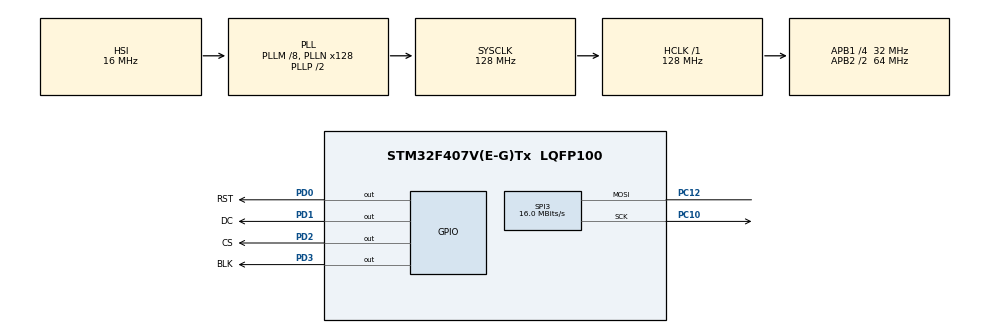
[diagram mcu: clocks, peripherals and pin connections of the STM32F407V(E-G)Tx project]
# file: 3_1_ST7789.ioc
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Mcu.Family=STM32F4
Mcu.Name=STM32F407V(E-G)Tx
Mcu.Package=LQFP100
NVIC.PriorityGroup=NVIC_PRIORITYGROUP_4
PC10.Mode=Simplex_Bidirectional_Master
PC10.Signal=SPI3_SCK
PC12.Mode=Simplex_Bidirectional_Master
PC12.Signal=SPI3_MOSI
PD0.GPIO_Label=RST
PD0.GPIO_PuPd=GPIO_PULLUP
PD0.Signal=GPIO_Output
PD1.GPIO_Label=DC
PD1.Signal=GPIO_Output
PD2.GPIO_Label=CS
PD2.GPIO_PuPd=GPIO_PULLUP
PD2.Signal=GPIO_Output
PD3.GPIO_Label=BLK
PD3.GPIO_PuPd=GPIO_PULLDOWN
PD3.Signal=GPIO_Output
ProjectManager.HeapSize=0x200
ProjectManager.StackSize=0x400
ProjectManager.TargetToolchain=STM32CubeIDE
RCC.48MHZClocksFreq_Value=64000000
RCC.AHBFreq_Value=128000000
RCC.APB1CLKDivider=RCC_HCLK_DIV4
RCC.APB1Freq_Value=32000000
RCC.APB1TimFreq_Value=64000000
RCC.APB2CLKDivider=RCC_HCLK_DIV2
RCC.APB2Freq_Value=64000000
RCC.APB2TimFreq_Value=128000000
RCC.CortexFreq_Value=128000000
RCC.HCLKFreq_Value=128000000
RCC.HSE_VALUE=25000000
RCC.HSI_VALUE=16000000
RCC.LSE_VALUE=32768
RCC.PLLM=8
RCC.PLLN=128
RCC.SYSCLKFreq_VALUE=128000000
RCC.SYSCLKSource=RCC_SYSCLKSOURCE_PLLCLK
RCC.VCOOutputFreq_Value=256000000
SPI3.CLKPolarity=SPI_POLARITY_LOW
SPI3.CalculateBaudRate=16.0 MBits/s
SPI3.Direction=SPI_DIRECTION_1LINE
SPI3.Mode=SPI_MODE_MASTER
SPI3.VirtualType=VM_MASTER
board=custom

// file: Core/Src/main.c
/* USER CODE BEGIN Header */
/**
  ******************************************************************************
  * @file           : main.c
  * @brief          : Main program body
  ******************************************************************************
  * @attention
  *
  * Copyright (c) 2024 STMicroelectronics.
  * All rights reserved.
  *
  * This software is licensed under terms that can be found in the LICENSE file
  * in the root directory of this software component.
  * If no LICENSE file comes with this software, it is provided AS-IS.
  *
  ******************************************************************************
  */
/* USER CODE END Header */
#include <ST7789.h>
#include "main.h"
#include "spi.h"
#include "gpio.h"

void SystemClock_Config(void);

int main(void)
{

  /* MCU Configuration--------------------------------------------------------*/

  /* Reset of all peripherals, Initializes the Flash interface and the Systick. */
  HAL_Init();

  /* Configure the system clock */
  SystemClock_Config();

  /* Initialize all configured peripherals */
  MX_GPIO_Init();
  MX_SPI3_Init();
  /* USER CODE BEGIN 2 */
  ST7789_Init();
  ST7789_DrawAradLogo();
  /* USER CODE END 2 */

  /* Infinite loop */
  while (1)
  {

  }
}

void SystemClock_Config(void)
{
  RCC_OscInitTypeDef RCC_OscInitStruct = {0};
  RCC_ClkInitTypeDef RCC_ClkInitStruct = {0};

  /** Configure the main internal regulator output voltage
  */
  __HAL_RCC_PWR_CLK_ENABLE();
  __HAL_PWR_VOLTAGESCALING_CONFIG(PWR_REGULATOR_VOLTAGE_SCALE1);

  /** Initializes the RCC Oscillators according to the specified parameters
  * in the RCC_OscInitTypeDef structure.
  */
  RCC_OscInitStruct.OscillatorType = RCC_OSCILLATORTYPE_HSI;
  RCC_OscInitStruct.HSIState = RCC_HSI_ON;
  RCC_OscInitStruct.HSICalibrationValue = RCC_HSICALIBRATION_DEFAULT;
  RCC_OscInitStruct.PLL.PLLState = RCC_PLL_ON;
  RCC_OscInitStruct.PLL.PLLSource = RCC_PLLSOURCE_HSI;
  RCC_OscInitStruct.PLL.PLLM = 8;
  RCC_OscInitStruct.PLL.PLLN = 128;
  RCC_OscInitStruct.PLL.PLLP = RCC_PLLP_DIV2;
  RCC_OscInitStruct.PLL.PLLQ = 4;
  if (HAL_RCC_OscConfig(&RCC_OscInitStruct) != HAL_OK)
  {
    Error_Handler();
  }

  /** Initializes the CPU, AHB and APB buses clocks
  */
  RCC_ClkInitStruct.ClockType = RCC_CLOCKTYPE_HCLK|RCC_CLOCKTYPE_SYSCLK
                              |RCC_CLOCKTYPE_PCLK1|RCC_CLOCKTYPE_PCLK2;
  RCC_ClkInitStruct.SYSCLKSource = RCC_SYSCLKSOURCE_PLLCLK;
  RCC_ClkInitStruct.AHBCLKDivider = RCC_SYSCLK_DIV1;
  RCC_ClkInitStruct.APB1CLKDivider = RCC_HCLK_DIV4;
  RCC_ClkInitStruct.APB2CLKDivider = RCC_HCLK_DIV2;

  if (HAL_RCC_ClockConfig(&RCC_ClkInitStruct, FLASH_LATENCY_4) != HAL_OK)
  {
    Error_Handler();
  }
}

void Error_Handler(void)
{
  __disable_irq();
  while (1)
  {
  }
}
